# ATSAMR35J18B register map
Vendor: Microchip Technology Inc.; Series: SAMR35; File version: B
CPU: CM0+ r0p1, little endian, no MPU, no FPU, VTOR, 2 interrupt priority bits, 29 interrupts
Registers are 32-bit, read-write, reset 0x0 unless marked. A register's access mark holds for its fields unless they carry their own. Offsets are from the block's base; [hi:lo] are bit positions; {n}, {i} and the like mark numbered series; 'fields as' and 'values as' point back to an identical list.

## PM — Power Manager
Base 0x40000000; register names take the prefix PM_
0x00 CTRLA 8-bit — Control A
  [2] IORET — I/O Retention
0x01 SLEEPCFG 8-bit reset 0x2 — Sleep Configuration
  [2:0] SLEEPMODE
    2=IDLE (CPU, AHBx, and APBx clocks are OFF); 4=STANDBY (All Clocks are OFF); 5=BACKUP (Only Backup domain is powered ON); 6=OFF (All power domains are powered OFF)
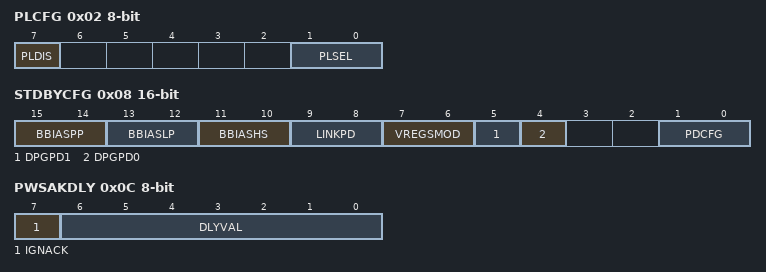
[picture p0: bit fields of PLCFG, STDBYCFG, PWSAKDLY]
0x02 PLCFG 8-bit — Performance Level Configuration
  [7] PLDIS — Performance Level Disable
  [1:0] PLSEL — Performance Level Select
    0=PL0 (Performance Level 0); 1=PL1 (Performance Level 1); 2=PL2 (Performance Level 2)
0x04 INTENCLR 8-bit — Interrupt Enable Clear
  [0] PLRDY wo — Performance Level Interrupt Enable
0x05 INTENSET 8-bit — Interrupt Enable Set
  [0] PLRDY — Performance Level Ready interrupt Enable
0x06 INTFLAG 8-bit — Interrupt Flag Status and Clear
  [0] PLRDY — Performance Level Ready
0x08 STDBYCFG 16-bit — Standby Configuration
  [15:14] BBIASPP — Back Bias for PicoPram
  [13:12] BBIASLP — Back Bias for HMCRAMCLP
  [11:10] BBIASHS — Back Bias for HMCRAMCHS
  [9:8] LINKPD — Linked Power Domain
    0=DEFAULT (Power domains are not linked); 1=PD01 (PD0 and PD1 power domains are linked); 2=PD12 (PD1 and PD2 power domains are linked); 3=PD012 (All power domains are linked)
  [7:6] VREGSMOD — Voltage Regulator Standby mode
    0=AUTO (Automatic mode); 1=PERFORMANCE (Performance oriented); 2=LP (Low Power oriented)
  [5] DPGPD1 — Dynamic Power Gating for PD1
  [4] DPGPD0 — Dynamic Power Gating for PD0
  [1:0] PDCFG — Power Domain Configuration
    0=DEFAULT (All power domains switching is handled by hardware.); 1=PD0 (PD0 is forced ACTIVE. PD1 and PD2 power domains switching is handled by hardware.); 2=PD01 (PD0 and PD1 are forced ACTIVE. PD2 power domain switching is handled by hardware.); 3=PD012 (All power domains are forced ACTIVE.)
0x0C PWSAKDLY 8-bit — Power Switch Acknowledge Delay
  [7] IGNACK — Ignore Acknowledge
  [6:0] DLYVAL — Delay Value

## PORT — Port Module
Base 0x40002800; register names take the prefix PORT_
Same registers: PORT_IOBUS 0x60000000 (register names take the prefix PORT_IOBUS_)
{0x0+0x80*i} DIR{i} (i=0..2) — Data Direction
  [31:0] DIR — Port Data Direction
{0x4+0x80*i} DIRCLR{i} (i=0..2) — Data Direction Clear
  [31:0] DIRCLR — Port Data Direction Clear
{0x8+0x80*i} DIRSET{i} (i=0..2) — Data Direction Set
  [31:0] DIRSET — Port Data Direction Set
{0xC+0x80*i} DIRTGL{i} (i=0..2) — Data Direction Toggle
  [31:0] DIRTGL — Port Data Direction Toggle
{0x10+0x80*i} OUT{i} (i=0..2) — Data Output Value
  [31:0] OUT — Port Data Output Value
{0x14+0x80*i} OUTCLR{i} (i=0..2) — Data Output Value Clear
  [31:0] OUTCLR — Port Data Output Value Clear
{0x18+0x80*i} OUTSET{i} (i=0..2) — Data Output Value Set
  [31:0] OUTSET — Port Data Output Value Set
{0x1C+0x80*i} OUTTGL{i} (i=0..2) — Data Output Value Toggle
  [31:0] OUTTGL — Port Data Output Value Toggle
{0x20+0x80*i} IN{i} (i=0..2) ro — Data Input Value
  [31:0] IN — Port Data Input Value
{0x24+0x80*i} CTRL{i} (i=0..2) — Control
  [31:0] SAMPLING wo — Input Sampling Mode
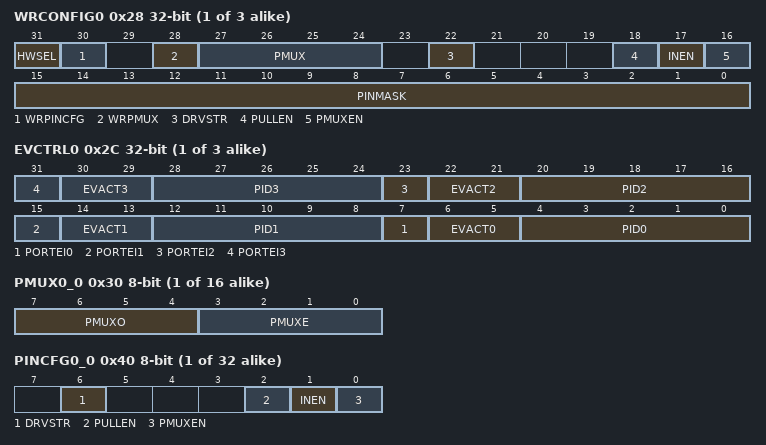
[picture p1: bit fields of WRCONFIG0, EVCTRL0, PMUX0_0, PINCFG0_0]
{0x28+0x80*i} WRCONFIG{i} (i=0..2) wo — Write Configuration
  [31] HWSEL — Half-Word Select
  [30] WRPINCFG — Write PINCFG Registers
  [28] WRPMUX — Write PMUX Registers
  [27:24] PMUX — Peripheral Multiplexing Template
  [22] DRVSTR — Output Driver Strength Selection
  [18] PULLEN — Pull Enable
  [17] INEN — Input Enable
  [16] PMUXEN — Select Peripheral Multiplexer
  [15:0] PINMASK — Pin Mask for Multiple Pin Configuration
{0x2C+0x80*i} EVCTRL{i} (i=0..2) — Event Input Control
  [8n+7] PORTEI{n} (n=0..3) — Port Event Enable Input {n}
  [8n+6:8n+5] EVACT{n} (n=0..3) — Port Event Action {n}
  [8n+4:8n] PID{n} (n=0..3) — Port Event Pin Identifier {n}
{0x30+i} PMUX0_{i} (i=0..15) 8-bit — Peripheral Multiplexing n - Group 0
  [7:4] PMUXO — Peripheral Multiplexing for Odd-Numbered Pin
  [3:0] PMUXE — Peripheral Multiplexing for Even-Numbered Pin
{0x40+i} PINCFG0_{i} (i=0..31) 8-bit — Pin Configuration n - Group 0
  [6] DRVSTR wo — Output Driver Strength Selection
  [2] PULLEN — Pull Enable
  [1] INEN — Input Enable
  [0] PMUXEN — Select Peripheral Multiplexer
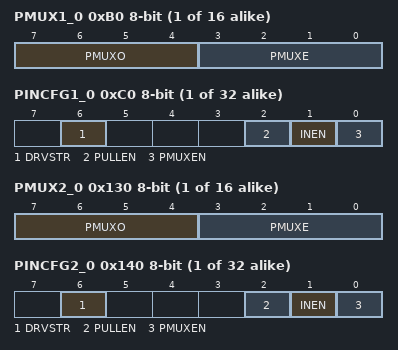
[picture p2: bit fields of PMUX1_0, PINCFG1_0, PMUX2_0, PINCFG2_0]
{0xB0+i} PMUX1_{i} (i=0..15) 8-bit — Peripheral Multiplexing n - Group 1
  fields as PMUX0_0
{0xC0+i} PINCFG1_{i} (i=0..31) 8-bit — Pin Configuration n - Group 1
  fields as PINCFG0_0
{0x130+i} PMUX2_{i} (i=0..15) 8-bit — Peripheral Multiplexing n - Group 2
  fields as PMUX0_0
{0x140+i} PINCFG2_{i} (i=0..31) 8-bit — Pin Configuration n - Group 2
  fields as PINCFG0_0

## RSTC — Reset Controller
Base 0x40000800; register names take the prefix RSTC_
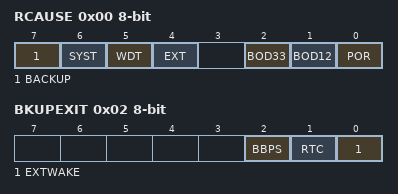
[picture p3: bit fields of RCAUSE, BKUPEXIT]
0x00 RCAUSE 8-bit ro — Reset Cause
  [7] BACKUP — Backup Reset
  [6] SYST — System Reset Request
  [5] WDT — Watchdog Reset
  [4] EXT — External Reset
  [2] BOD33 — Brown Out 33 Detector Reset
  [1] BOD12 — Brown Out 12 Detector Reset
  [0] POR — Power On Reset
0x02 BKUPEXIT 8-bit ro — Backup Exit Source
  [2] BBPS — Battery Backup Power Switch
  [1] RTC — Real Timer Counter Interrupt
  [0] EXTWAKE — External Wakeup
0x04 WKDBCONF 8-bit — Wakeup Debounce Configuration
  [4:0] WKDBCNT — Wakeup Debounce Counter
    0=OFF (No debouncing.Input pin is low or high level sensitive depending on its WKPOLx bit.); 1=2CK32 (Input pin shall be active for at least two 32kHz clock period.); 2=3CK32 (Input pin shall be active for at least three 32kHz clock period.); 3=32CK32 (Input pin shall be active for at least 32 32kHz clock period.); 4=512CK32 (Input pin shall be active for at least 512 32kHz clock period.); 5=4096CK32 (Input pin shall be active for at least 4096 32kHz clock period.); 6=32768CK32 (Input pin shall be active for at least 32768 32kHz clock period.)
0x08 WKPOL 16-bit — Wakeup Polarity
  [7:0] WKPOL
0x0C WKEN 16-bit — Wakeup Enable
  [7:0] WKEN
0x10 WKCAUSE 16-bit — Wakeup Cause
  [15:0] WKCAUSE ro

## TRNG — True Random Generator
Base 0x42003800; register names take the prefix TRNG_
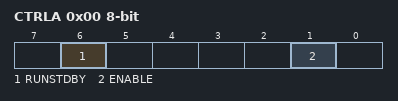
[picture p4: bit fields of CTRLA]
0x00 CTRLA 8-bit — Control A
  [6] RUNSTDBY — Run in Standby
  [1] ENABLE
0x04 EVCTRL 8-bit — Event Control
  [0] DATARDYEO — Data Ready Event Output
0x08 INTENCLR 8-bit — Interrupt Enable Clear
  [0] DATARDY — Data Ready Interrupt Enable
0x09 INTENSET 8-bit — Interrupt Enable Set
  [0] DATARDY — Data Ready Interrupt Enable
0x0A INTFLAG 8-bit — Interrupt Flag Status and Clear
  [0] DATARDY — Data Ready Interrupt Flag
0x20 DATA ro — Output Data

## WDT — Watchdog Timer
Base 0x40001C00; register names take the prefix WDT_
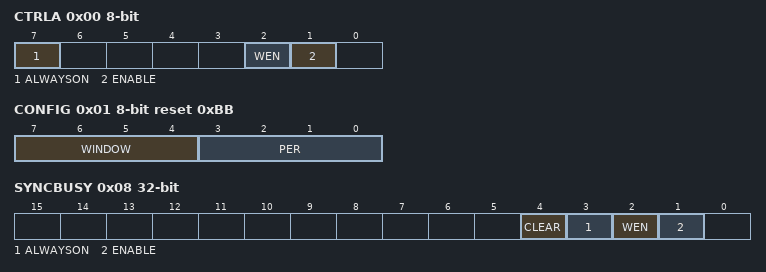
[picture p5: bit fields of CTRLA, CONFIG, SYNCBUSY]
0x00 CTRLA 8-bit — Control
  [7] ALWAYSON
  [2] WEN — Watchdog Timer Window Mode Enable
  [1] ENABLE
0x01 CONFIG 8-bit reset 0xBB — Configuration
  [7:4] WINDOW — Window Mode Time-Out Period
    0=CYC8 (8 clock cycles); 1=CYC16 (16 clock cycles); 2=CYC32 (32 clock cycles); 3=CYC64 (64 clock cycles); 4=CYC128 (128 clock cycles); 5=CYC256 (256 clock cycles); 6=CYC512 (512 clock cycles); 7=CYC1024 (1024 clock cycles); 8=CYC2048 (2048 clock cycles); 9=CYC4096 (4096 clock cycles); 10=CYC8192 (8192 clock cycles); 11=CYC16384 (16384 clock cycles)
  [3:0] PER — Time-Out Period
    values as WINDOW
0x02 EWCTRL 8-bit reset 0xB — Early Warning Interrupt Control
  [3:0] EWOFFSET — Early Warning Interrupt Time Offset
    values as CONFIG.WINDOW
0x04 INTENCLR 8-bit — Interrupt Enable Clear
  [0] EW — Early Warning Interrupt Enable
0x05 INTENSET 8-bit — Interrupt Enable Set
  [0] EW — Early Warning Interrupt Enable
0x06 INTFLAG 8-bit — Interrupt Flag Status and Clear
  [0] EW — Early Warning
0x08 SYNCBUSY ro — Synchronization Busy
  [4] CLEAR — Clear Busy
  [3] ALWAYSON — Always-On Busy
  [2] WEN — Window Enable Busy
  [1] ENABLE — Enable Busy
0x0C CLEAR 8-bit wo
  [7:0] CLEAR — Watchdog Clear
    165=KEY (Clear Key)

## Notices in the file
Copyright (c) 2018 Microchip Technology Inc.
SPDX-License-Identifier: Apache-2.0
Licensed under the Apache License, Version 2.0 (the "License");
you may not use this file except in compliance with the License.
You may obtain a copy of the License at
http://www.apache.org/licenses/LICENSE-2.0
Unless required by applicable law or agreed to in writing, software
distributed under the License is distributed on an "AS IS" BASIS,
WITHOUT WARRANTIES OR CONDITIONS OF ANY KIND, either express or implied.
See the License for the specific language governing permissions and
limitations under the License.
